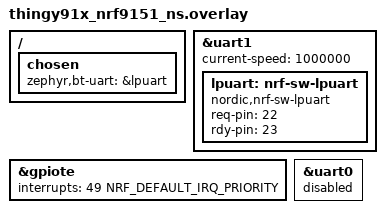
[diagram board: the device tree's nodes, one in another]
&uart1 {
	current-speed = <1000000>;
	status = "okay";

	lpuart: nrf-sw-lpuart {
		compatible = "nordic,nrf-sw-lpuart";
		status = "okay";
		req-pin = <22>;
		rdy-pin = <23>;
	};
};
/ {
	chosen {
		zephyr,bt-uart=&lpuart;
	};
};

&gpiote {
	interrupts = <49 NRF_DEFAULT_IRQ_PRIORITY>;
};

&uart0 {
	status = "disabled";
};
